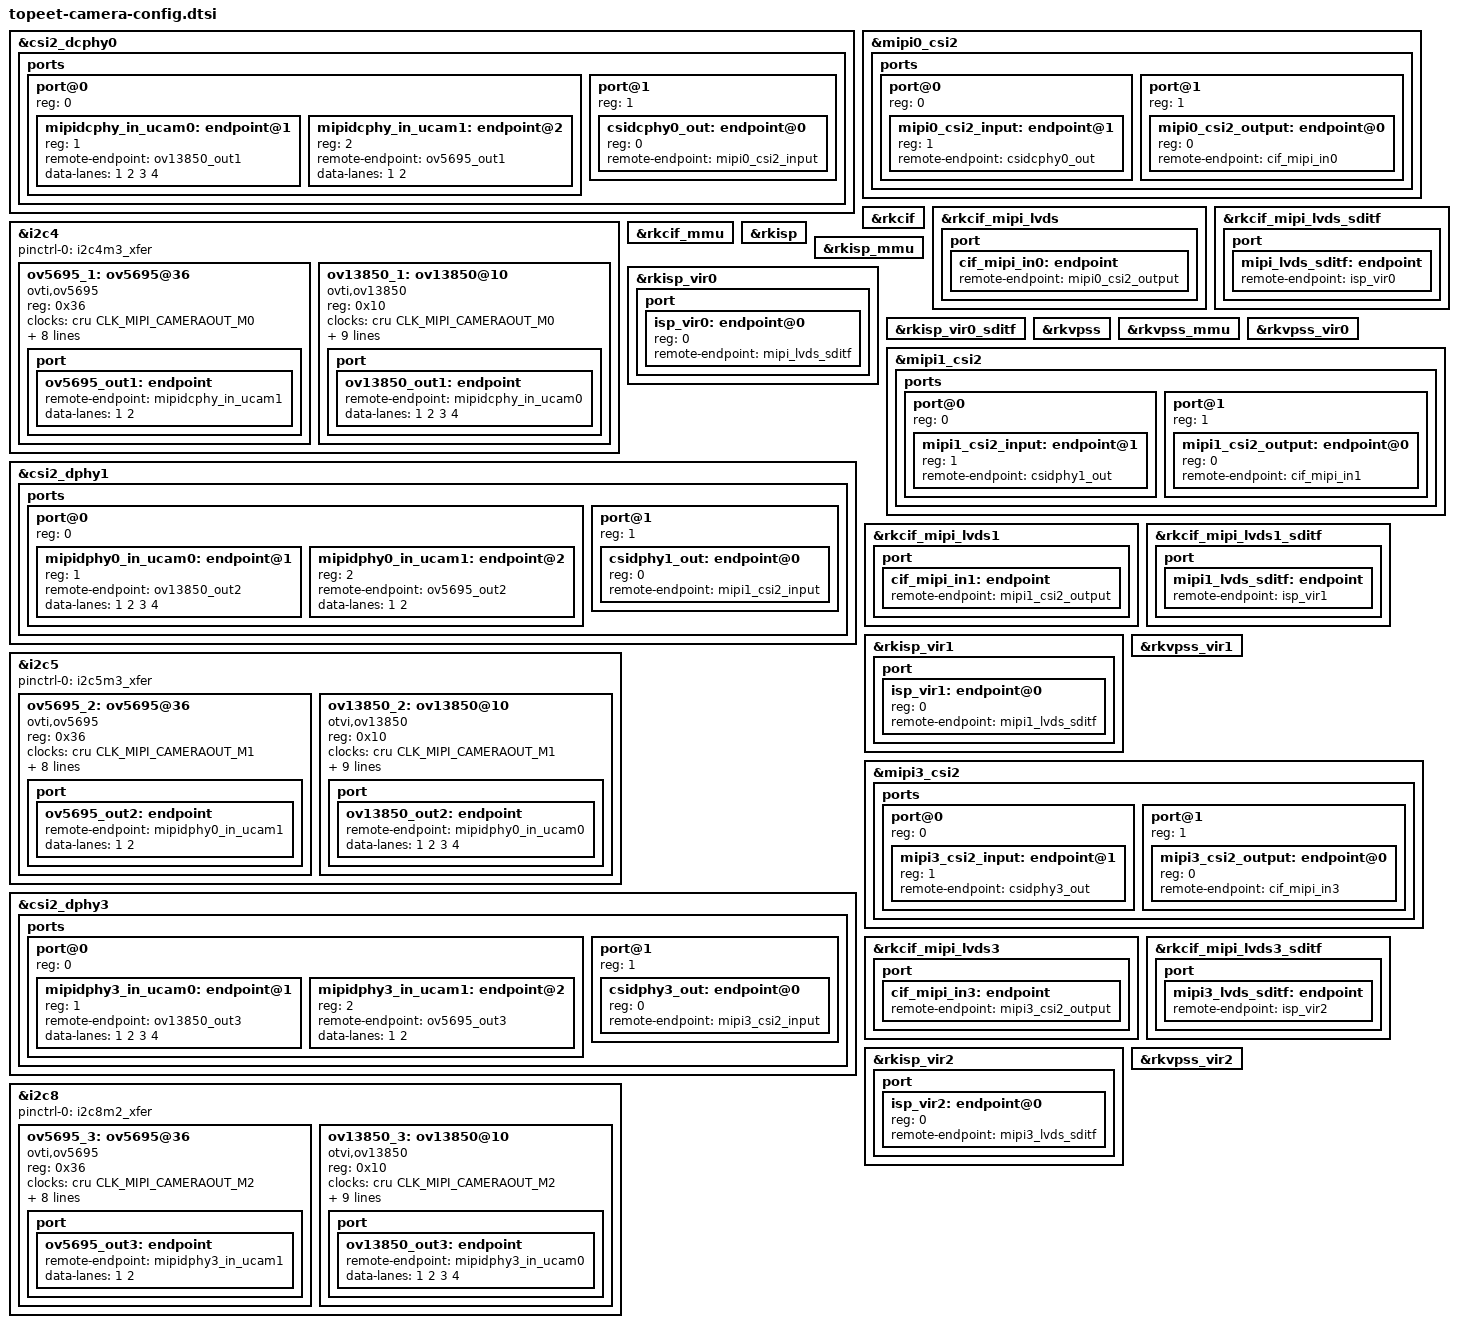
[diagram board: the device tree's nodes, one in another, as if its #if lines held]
//#define CAMERA_J1  //U16
#define CAMERA_J2  //U18
//#define CAMERA_J3  //U19 

#if defined(CAMERA_J1)
&csi2_dcphy0 {
    status = "okay";

    ports {
        #address-cells = <1>;
        #size-cells = <0>;
        port@0 {
            reg = <0>;
            #address-cells = <1>;
            #size-cells = <0>;

            mipidcphy_in_ucam0: endpoint@1 {
                reg = <1>;
                remote-endpoint = <&ov13850_out1>;
                data-lanes = <1 2 3 4>;
            };

            mipidcphy_in_ucam1: endpoint@2 {
                reg = <2>;
                remote-endpoint = <&ov5695_out1>;
                data-lanes = <1 2>;
            };
        };
        port@1 {
            reg = <1>;
            #address-cells = <1>;
            #size-cells = <0>;

            csidcphy0_out: endpoint@0 {
                reg = <0>;
                remote-endpoint = <&mipi0_csi2_input>;
            };
        };
    };
};

&i2c4 {
    status = "okay";
    pinctrl-0 = <&i2c4m3_xfer>;

    ov5695_1: ov5695@36 {
        status = "okay";
        compatible = "ovti,ov5695";
        reg = <0x36>;
        clocks = <&cru CLK_MIPI_CAMERAOUT_M0>;
        clock-names = "xvclk";
        power-domains = <&power RK3576_PD_VI>;
        pinctrl-names = "default";
        pinctrl-0 = <&cam_clk0m0_clk0>;
        reset-gpios = <&gpio1 RK_PD3 GPIO_ACTIVE_LOW>;
        pwdn-gpios = <&gpio3 RK_PC7 GPIO_ACTIVE_LOW>;
        rockchip,camera-module-index = <0>;
        rockchip,camera-module-facing = "back";
        rockchip,camera-module-name = "default";
        rockchip,camera-module-lens-name = "default";
        port {
            ov5695_out1: endpoint {
                remote-endpoint = <&mipidcphy_in_ucam1>;
                data-lanes = <1 2>;
            };
        };
    };

    ov13850_1: ov13850@10 {
        status = "okay";
        compatible = "ovti,ov13850";
        reg = <0x10>;
        clocks = <&cru CLK_MIPI_CAMERAOUT_M0>;
        clock-names = "xvclk";
        power-domains = <&power RK3576_PD_VI>;
        pinctrl-names = "default";
        pinctrl-0 = <&cam_clk0m0_clk0>;
        reset-gpios = <&gpio1 RK_PD3 GPIO_ACTIVE_HIGH>;
        pwdn-gpios = <&gpio3 RK_PC7 GPIO_ACTIVE_HIGH>;
        rockchip,camera-module-index = <1>;
        rockchip,camera-module-facing = "back";
        rockchip,camera-module-name = "CMK-CT0116";
        rockchip,camera-module-lens-name = "Largan-50013A1";
        port {
            ov13850_out1: endpoint {
                remote-endpoint = <&mipidcphy_in_ucam0>;
                data-lanes = <1 2 3 4>;
            };
        };
    };
};

&mipi0_csi2 {
    status = "okay";

    ports {
        #address-cells = <1>;
        #size-cells = <0>;

        port@0 {
            reg = <0>;
            #address-cells = <1>;
            #size-cells = <0>;

            mipi0_csi2_input: endpoint@1 {
                reg = <1>;
                remote-endpoint = <&csidcphy0_out>;
            };
        };

        port@1 {
            reg = <1>;
            #address-cells = <1>;
            #size-cells = <0>;

            mipi0_csi2_output: endpoint@0 {
                reg = <0>;
                remote-endpoint = <&cif_mipi_in0>;
            };
        };
    };
};

&rkcif {
    status = "okay";
};

&rkcif_mipi_lvds {
    status = "okay";

    port {
        cif_mipi_in0: endpoint {
            remote-endpoint = <&mipi0_csi2_output>;
        };
    };
};

&rkcif_mipi_lvds_sditf {
    status = "okay";

    port {
        mipi_lvds_sditf: endpoint {
            remote-endpoint = <&isp_vir0>;
        };
    };
};

&rkcif_mmu {
    status = "okay";
};

&rkisp {
    status = "okay";
};

&rkisp_mmu {
    status = "okay";
};

&rkisp_vir0 {
    status = "okay";

    port {
        #address-cells = <1>;
        #size-cells = <0>;

        isp_vir0: endpoint@0 {
            reg = <0>;
            remote-endpoint = <&mipi_lvds_sditf>;
        };
    };
};

&rkisp_vir0_sditf {
    status = "okay";
};

&rkvpss {
    status = "okay";
};

&rkvpss_mmu {
    status = "okay";
};

&rkvpss_vir0 {
    status = "okay";
};
#endif


#if defined(CAMERA_J2)
&csi2_dphy1 {
	status = "okay";

	ports {
		#address-cells = <1>;
		#size-cells = <0>;
		port@0 {
			reg = <0>;
			#address-cells = <1>;
			#size-cells = <0>;

			mipidphy0_in_ucam0: endpoint@1 {
				reg = <1>;
				remote-endpoint = <&ov13850_out2>;
				data-lanes = <1 2 3 4>;
			};

			mipidphy0_in_ucam1: endpoint@2 {
				reg = <2>;
				remote-endpoint = <&ov5695_out2>;
				data-lanes = <1 2>;
			};
		};
		port@1 {
			reg = <1>;
			#address-cells = <1>;
			#size-cells = <0>;

			csidphy1_out: endpoint@0 {
				reg = <0>;
				remote-endpoint = <&mipi1_csi2_input>;
			};
		};
	};
};

&i2c5 {
	status = "okay";
	pinctrl-0 = <&i2c5m3_xfer>;

	ov5695_2: ov5695@36 {
		status = "okay";
		compatible = "ovti,ov5695";
		reg = <0x36>;
		clocks = <&cru CLK_MIPI_CAMERAOUT_M1>;
		clock-names = "xvclk";
		power-domains = <&power RK3576_PD_VI>;
		pinctrl-names = "default";
		pinctrl-0 = <&cam_clk1m0_clk1>;
		reset-gpios = <&gpio3 RK_PC5 GPIO_ACTIVE_LOW>;
		pwdn-gpios = <&gpio3 RK_PD0 GPIO_ACTIVE_LOW>;
		rockchip,camera-module-index = <0>;
		rockchip,camera-module-facing = "back";
		rockchip,camera-module-name = "default";
		rockchip,camera-module-lens-name = "default";
		port {
			ov5695_out2: endpoint {
				remote-endpoint = <&mipidphy0_in_ucam1>;
				data-lanes = <1 2>;
			};
		};
	};

	ov13850_2: ov13850@10 {
		status = "okay";
		compatible = "otvi,ov13850";
		reg = <0x10>;
		clocks = <&cru CLK_MIPI_CAMERAOUT_M1>;
		clock-names = "xvclk";
		power-domains = <&power RK3576_PD_VI>;
		pinctrl-names = "default";
		pinctrl-0 = <&cam_clk1m0_clk1>;
		reset-gpios = <&gpio3 RK_PC5 GPIO_ACTIVE_HIGH>;
		pwdn-gpios = <&gpio3 RK_PD0 GPIO_ACTIVE_HIGH>;
		rockchip,camera-module-index = <1>;
		rockchip,camera-module-facing = "back";
		rockchip,camera-module-name = "CMK-CT0116";
		rockchip,camera-module-lens-name = "Largan-50013A1";
		port {
			ov13850_out2: endpoint {
				remote-endpoint = <&mipidphy0_in_ucam0>;
				data-lanes = <1 2 3 4>;
			};
		};
	};
};


&mipi1_csi2 {
	status = "okay";

	ports {
		#address-cells = <1>;
		#size-cells = <0>;

		port@0 {
			reg = <0>;
			#address-cells = <1>;
			#size-cells = <0>;

			mipi1_csi2_input: endpoint@1 {
				reg = <1>;
				remote-endpoint = <&csidphy1_out>;
			};
		};

		port@1 {
			reg = <1>;
			#address-cells = <1>;
			#size-cells = <0>;

			mipi1_csi2_output: endpoint@0 {
				reg = <0>;
				remote-endpoint = <&cif_mipi_in1>;
			};
		};
	};
};

&rkcif {
	status = "okay";
};
&rkcif_mipi_lvds1 {
	status = "okay";

	port {
		cif_mipi_in1: endpoint {
			remote-endpoint = <&mipi1_csi2_output>;
		};
	};
};

&rkcif_mipi_lvds1_sditf {
	status = "okay";

	port {
		mipi1_lvds_sditf: endpoint {
			remote-endpoint = <&isp_vir1>;
		};
	};
};

&rkcif_mmu {
	status = "okay";
};

&rkisp {
	status = "okay";
};

&rkisp_mmu {
	status = "okay";
};

&rkisp_vir1 {
	status = "okay";

	port {
		#address-cells = <1>;
		#size-cells = <0>;

		isp_vir1: endpoint@0 {
			reg = <0>;
			remote-endpoint = <&mipi1_lvds_sditf>;
		};
	};
};

&rkvpss {
	status = "okay";
};

&rkvpss_mmu {
	status = "okay";
};

&rkvpss_vir1 {
	status = "okay";
};

#endif


#if defined(CAMERA_J3)
&csi2_dphy3 {
	status = "okay";

	ports {
		#address-cells = <1>;
		#size-cells = <0>;
		port@0 {
			reg = <0>;
			#address-cells = <1>;
			#size-cells = <0>;

			mipidphy3_in_ucam0: endpoint@1 {
				reg = <1>;
				remote-endpoint = <&ov13850_out3>;
				data-lanes = <1 2 3 4>;
			};

			mipidphy3_in_ucam1: endpoint@2 {
				reg = <2>;
				remote-endpoint = <&ov5695_out3>;
				data-lanes = <1 2>;
			};
		};
		port@1 {
			reg = <1>;
			#address-cells = <1>;
			#size-cells = <0>;

			csidphy3_out: endpoint@0 {
				reg = <0>;
				remote-endpoint = <&mipi3_csi2_input>;
			};
		};
	};
};

&i2c8 {
	status = "okay";
	pinctrl-0 = <&i2c8m2_xfer>;

	ov5695_3: ov5695@36 {
		status = "okay";
		compatible = "ovti,ov5695";
		reg = <0x36>;
		clocks = <&cru CLK_MIPI_CAMERAOUT_M2>;
		clock-names = "xvclk";
		power-domains = <&power RK3576_PD_VI>;
		pinctrl-names = "default";
		pinctrl-0 = <&cam_clk2m0_clk2>;
		reset-gpios = <&gpio3 RK_PC6 GPIO_ACTIVE_LOW>;
		pwdn-gpios = <&gpio3 RK_PD5 GPIO_ACTIVE_LOW>;
		rockchip,camera-module-index = <0>;
		rockchip,camera-module-facing = "back";
		rockchip,camera-module-name = "default";
		rockchip,camera-module-lens-name = "default";
		port {
			ov5695_out3: endpoint {
				remote-endpoint = <&mipidphy3_in_ucam1>;
				data-lanes = <1 2>;
			};
		};
	};

	ov13850_3: ov13850@10 {
		status = "okay";
		compatible = "otvi,ov13850";
		reg = <0x10>;
		clocks = <&cru CLK_MIPI_CAMERAOUT_M2>;
		clock-names = "xvclk";
		power-domains = <&power RK3576_PD_VI>;
		pinctrl-names = "default";
		pinctrl-0 = <&cam_clk2m0_clk2>;
		reset-gpios = <&gpio3 RK_PC6 GPIO_ACTIVE_HIGH>;
		pwdn-gpios = <&gpio3 RK_PD5 GPIO_ACTIVE_HIGH>;
		rockchip,camera-module-index = <1>;
		rockchip,camera-module-facing = "back";
		rockchip,camera-module-name = "CMK-CT0116";
		rockchip,camera-module-lens-name = "Largan-50013A1";
		port {
			ov13850_out3: endpoint {
				remote-endpoint = <&mipidphy3_in_ucam0>;
				data-lanes = <1 2 3 4>;
			};
		};
	};
};

&mipi3_csi2 {
	status = "okay";

	ports {
		#address-cells = <1>;
		#size-cells = <0>;

		port@0 {
			reg = <0>;
			#address-cells = <1>;
			#size-cells = <0>;

			mipi3_csi2_input: endpoint@1 {
				reg = <1>;
				remote-endpoint = <&csidphy3_out>;
			};
		};

		port@1 {
			reg = <1>;
			#address-cells = <1>;
			#size-cells = <0>;

			mipi3_csi2_output: endpoint@0 {
				reg = <0>;
				remote-endpoint = <&cif_mipi_in3>;
			};
		};
	};
};

&rkcif {
	status = "okay";
};

&rkcif_mipi_lvds3 {
	status = "okay";

	port {
		cif_mipi_in3: endpoint {
			remote-endpoint = <&mipi3_csi2_output>;
		};
	};
};

&rkcif_mipi_lvds3_sditf {
	status = "okay";

	port {
		mipi3_lvds_sditf: endpoint {
			remote-endpoint = <&isp_vir2>;
		};
	};
};

&rkcif_mmu {
	status = "okay";
};

&rkisp {
	status = "okay";
};

&rkisp_mmu {
	status = "okay";
};

&rkisp_vir2 {
	status = "okay";

	port {
		#address-cells = <1>;
		#size-cells = <0>;

		isp_vir2: endpoint@0 {
			reg = <0>;
			remote-endpoint = <&mipi3_lvds_sditf>;
		};
	};
};

&rkvpss {
	status = "okay";
};

&rkvpss_mmu {
	status = "okay";
};

&rkvpss_vir2 {
	status = "okay";
};

#endif
